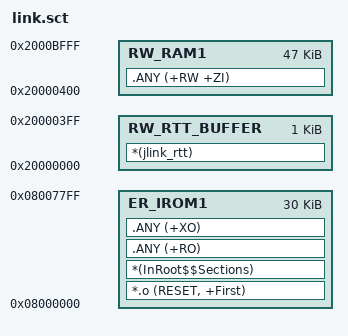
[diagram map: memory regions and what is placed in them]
LR_IROM1 0x08000000 0x7800 {
	ER_IROM1 0x08000000 0x7800 {
		*.o (RESET, +First)
		*(InRoot$$Sections)
		.ANY (+RO)
		.ANY (+XO)
	}
	RW_RAM1 0x20000400 0x0000BC00 { 
		.ANY (+RW +ZI)
	}

	; 在RAM末尾为RTT预留512字节的专用段
	RW_RTT_BUFFER 0x20000000 0x00000400 {  ; 1K
		*(jlink_rtt)    ; 与 SEGGER_RTT_SECTION 定义匹配
	}
}

